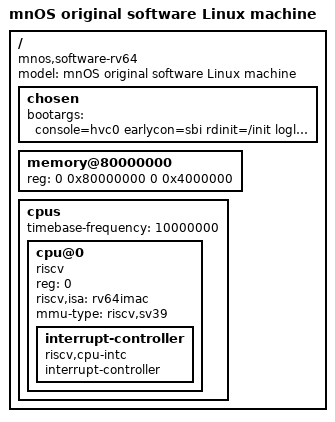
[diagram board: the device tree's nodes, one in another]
/dts-v1/;
/ {
    #address-cells = <2>; #size-cells = <2>;
    compatible = "mnos,software-rv64";
    model = "mnOS original software Linux machine";
    chosen { bootargs = "console=hvc0 earlycon=sbi rdinit=/init loglevel=5 nokaslr"; };
    memory@80000000 { device_type = "memory"; reg = <0 0x80000000 0 0x4000000>; };
    cpus {
        #address-cells = <1>; #size-cells = <0>; timebase-frequency = <10000000>;
        cpu@0 {
            device_type = "cpu"; reg = <0>; status = "okay";
            compatible = "riscv"; riscv,isa = "rv64imac"; mmu-type = "riscv,sv39";
            interrupt-controller { #interrupt-cells = <1>; interrupt-controller; compatible = "riscv,cpu-intc"; };
        };
    };
};
